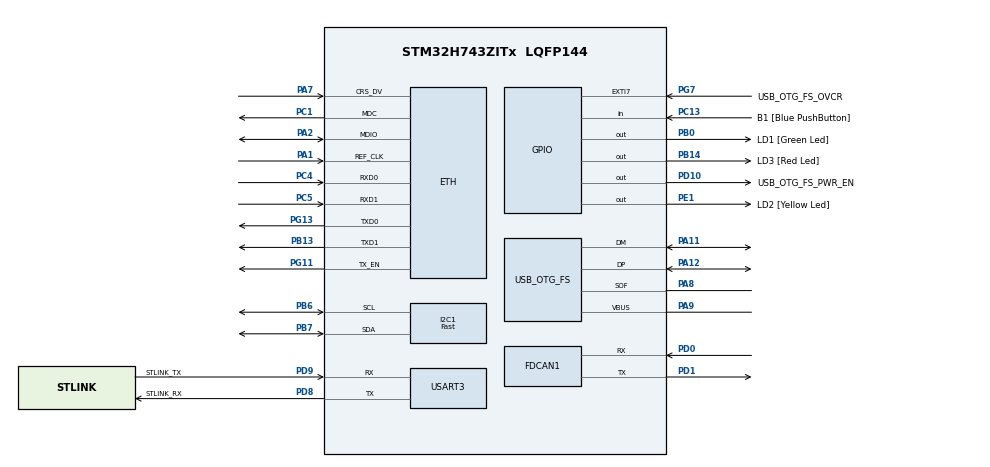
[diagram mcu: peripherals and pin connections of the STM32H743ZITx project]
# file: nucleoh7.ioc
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Dma.I2C1_RX.0.Direction=DMA_PERIPH_TO_MEMORY
Dma.I2C1_RX.0.EventEnable=DISABLE
Dma.I2C1_RX.0.FIFOMode=DMA_FIFOMODE_DISABLE
Dma.I2C1_RX.0.Instance=DMA1_Stream0
Dma.I2C1_RX.0.MemDataAlignment=DMA_MDATAALIGN_BYTE
Dma.I2C1_RX.0.MemInc=DMA_MINC_ENABLE
Dma.I2C1_RX.0.Mode=DMA_NORMAL
Dma.I2C1_RX.0.PeriphDataAlignment=DMA_PDATAALIGN_BYTE
Dma.I2C1_RX.0.PeriphInc=DMA_PINC_DISABLE
Dma.I2C1_RX.0.Polarity=HAL_DMAMUX_REQ_GEN_RISING
Dma.I2C1_RX.0.Priority=DMA_PRIORITY_LOW
Dma.I2C1_RX.0.RequestNumber=1
Dma.I2C1_RX.0.SignalID=NONE
Dma.I2C1_RX.0.SyncEnable=DISABLE
Dma.I2C1_RX.0.SyncPolarity=HAL_DMAMUX_SYNC_NO_EVENT
Dma.I2C1_RX.0.SyncRequestNumber=1
Dma.I2C1_RX.0.SyncSignalID=NONE
Dma.I2C1_TX.1.Direction=DMA_MEMORY_TO_PERIPH
Dma.I2C1_TX.1.EventEnable=DISABLE
Dma.I2C1_TX.1.FIFOMode=DMA_FIFOMODE_DISABLE
Dma.I2C1_TX.1.Instance=DMA1_Stream1
Dma.I2C1_TX.1.MemDataAlignment=DMA_MDATAALIGN_BYTE
Dma.I2C1_TX.1.MemInc=DMA_MINC_ENABLE
Dma.I2C1_TX.1.Mode=DMA_NORMAL
Dma.I2C1_TX.1.PeriphDataAlignment=DMA_PDATAALIGN_BYTE
Dma.I2C1_TX.1.PeriphInc=DMA_PINC_DISABLE
Dma.I2C1_TX.1.Polarity=HAL_DMAMUX_REQ_GEN_RISING
Dma.I2C1_TX.1.Priority=DMA_PRIORITY_LOW
Dma.I2C1_TX.1.RequestNumber=1
Dma.I2C1_TX.1.SignalID=NONE
Dma.I2C1_TX.1.SyncEnable=DISABLE
Dma.I2C1_TX.1.SyncPolarity=HAL_DMAMUX_SYNC_NO_EVENT
Dma.I2C1_TX.1.SyncRequestNumber=1
Dma.I2C1_TX.1.SyncSignalID=NONE
Dma.Request0=I2C1_RX
Dma.Request1=I2C1_TX
ETH.MediaInterface=HAL_ETH_RMII_MODE
FDCAN1.AutoRetransmission=ENABLE
I2C1.I2C_Speed_Mode=I2C_Fast
I2C1.Timing=0x00702991
Mcu.Family=STM32H7
Mcu.Name=STM32H743ZITx
Mcu.Package=LQFP144
NVIC.DMA1_Stream0_IRQn=true\:0\:0\:false\:false\:true\:false\:true
NVIC.DMA1_Stream1_IRQn=true\:0\:0\:false\:false\:true\:false\:true
NVIC.FDCAN1_IT0_IRQn=true\:0\:0\:false\:false\:true\:true\:true
NVIC.FDCAN1_IT1_IRQn=true\:0\:0\:false\:false\:true\:true\:true
NVIC.I2C1_ER_IRQn=true\:0\:0\:false\:false\:true\:true\:true
NVIC.I2C1_EV_IRQn=true\:0\:0\:false\:false\:true\:true\:true
NVIC.PriorityGroup=NVIC_PRIORITYGROUP_4
PA1.Mode=RMII
PA1.Signal=ETH_REF_CLK
PA11.Mode=Device_Only
PA11.Signal=USB_OTG_FS_DM
PA12.Mode=Device_Only
PA12.Signal=USB_OTG_FS_DP
PA2.Mode=RMII
PA2.Signal=ETH_MDIO
PA7.Mode=RMII
PA7.Signal=ETH_CRS_DV
PA8.Mode=Activate_SOF_FS
PA8.Signal=USB_OTG_FS_SOF
PA9.Mode=Activate_VBUS
PA9.Signal=USB_OTG_FS_VBUS
PB0.GPIO_Label=LD1 [Green Led]
PB0.Signal=GPIO_Output
PB13.Mode=RMII
PB13.Signal=ETH_TXD1
PB14.GPIO_Label=LD3 [Red Led]
PB14.Signal=GPIO_Output
PB6.Mode=I2C
PB6.Signal=I2C1_SCL
PB7.Mode=I2C
PB7.Signal=I2C1_SDA
PC1.Mode=RMII
PC1.Signal=ETH_MDC
PC13.GPIO_Label=B1 [Blue PushButton]
PC13.Signal=GPIO_Input
PC14-OSC32_IN\ (OSC32_IN).Mode=LSE-External-Oscillator
PC14-OSC32_IN\ (OSC32_IN).Signal=RCC_OSC32_IN
PC15-OSC32_OUT\ (OSC32_OUT).Mode=LSE-External-Oscillator
PC15-OSC32_OUT\ (OSC32_OUT).Signal=RCC_OSC32_OUT
PC4.Mode=RMII
PC4.Signal=ETH_RXD0
PC5.Mode=RMII
PC5.Signal=ETH_RXD1
PD0.Mode=FDCANMaster
PD0.Signal=FDCAN1_RX
PD1.Mode=FDCANMaster
PD1.Signal=FDCAN1_TX
PD10.GPIO_Label=USB_OTG_FS_PWR_EN
PD10.Signal=GPIO_Output
PD8.GPIO_Label=STLINK_RX
PD8.Mode=Asynchronous
PD8.Signal=USART3_TX
PD9.GPIO_Label=STLINK_TX
PD9.Mode=Asynchronous
PD9.Signal=USART3_RX
PE1.GPIO_Label=LD2 [Yellow Led]
PE1.Signal=GPIO_Output
PG11.Mode=RMII
PG11.Signal=ETH_TX_EN
PG13.Mode=RMII
PG13.Signal=ETH_TXD0
PG7.GPIO_Label=USB_OTG_FS_OVCR
PG7.Signal=GPXTI7
PH0-OSC_IN\ (PH0).Mode=HSE-External-Clock-Source
PH0-OSC_IN\ (PH0).Signal=RCC_OSC_IN
PH1-OSC_OUT\ (PH1).Signal=RCC_OSC_OUT
ProjectManager.HeapSize=0x200
ProjectManager.StackSize=0x400
ProjectManager.TargetToolchain=MDK-ARM V5.27
RCC.ADCFreq_Value=16125000
RCC.APB1Freq_Value=80000000
RCC.APB2Freq_Value=80000000
RCC.APB3Freq_Value=80000000
RCC.APB4Freq_Value=80000000
RCC.CortexFreq_Value=320000000
RCC.D1PPRE=RCC_APB3_DIV2
RCC.D2PPRE1=RCC_APB1_DIV2
RCC.D2PPRE2=RCC_APB2_DIV2
RCC.D3PPRE=RCC_APB4_DIV2
RCC.DIVM1=1
RCC.DIVN1=80
RCC.DIVQ1=4
RCC.FDCANCLockSelection=RCC_FDCANCLKSOURCE_HSE
RCC.HCLKFreq_Value=160000000
RCC.HPRE=RCC_HCLK_DIV2
RCC.HSE_VALUE=8000000
RCC.PLLFRACN=0
RCC.PLLSourceVirtual=RCC_PLLSOURCE_HSE
RCC.SYSCLKFreq_VALUE=320000000
RCC.SYSCLKSource=RCC_SYSCLKSOURCE_PLLCLK
RCC.USBCLockSelection=RCC_USBCLKSOURCE_HSI48
RCC.USBFreq_Value=48000000
USART3.VirtualMode-Asynchronous=VM_ASYNC
USB_OTG_FS.VirtualMode=Device_Only
board=NUCLEO-H743ZI2

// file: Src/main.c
/* USER CODE BEGIN Header */
/**
  ******************************************************************************
  * @file           : main.c
  * @brief          : Main program body
  ******************************************************************************
  * @attention
  *
  * <h2><center>&copy; Copyright (c) 2020 STMicroelectronics.
  * All rights reserved.</center></h2>
  *
  * This software component is licensed by ST under BSD 3-Clause license,
  * the "License"; You may not use this file except in compliance with the
  * License. You may obtain a copy of the License at:
  *                        opensource.org/licenses/BSD-3-Clause
  *
  ******************************************************************************
  */
/* USER CODE END Header */
#include "main.h"
#include "dma.h"
#include "eth.h"
#include "fdcan.h"
#include "i2c.h"
#include "usart.h"
#include "usb_otg.h"
#include "gpio.h"

/* USER CODE BEGIN Includes */

#include "testframework.h"
#include "stdio.h"

/* USER CODE END Includes */

void SystemClock_Config(void);

int main(void)
{

  /* MCU Configuration--------------------------------------------------------*/

  /* Reset of all peripherals, Initializes the Flash interface and the Systick. */
  HAL_Init();

  /* Configure the system clock */
  SystemClock_Config();

  /* Initialize all configured peripherals */
  MX_GPIO_Init();
  MX_DMA_Init();
  MX_ETH_Init();
  MX_USART3_UART_Init();
  MX_USB_OTG_FS_PCD_Init();
  MX_FDCAN1_Init();
  MX_I2C1_Init();
  /* USER CODE BEGIN 2 */

  testframework_init();

  char text[64] = {0};

  /* USER CODE END 2 */

  /* Infinite loop */
  while (1)
  {

      HAL_Delay(100);
      uint32_t now = HAL_GetTickFreq();
      testframework_tick();
      uint32_t duration = HAL_GetTickFreq() - now;
      snprintf(text, sizeof(char), "duration = %d ms", duration);
      testframework_puts(text);

  }
}

void SystemClock_Config(void)
{
  RCC_OscInitTypeDef RCC_OscInitStruct = {0};
  RCC_ClkInitTypeDef RCC_ClkInitStruct = {0};
  RCC_PeriphCLKInitTypeDef PeriphClkInitStruct = {0};

  /** Supply configuration update enable
  */
  HAL_PWREx_ConfigSupply(PWR_LDO_SUPPLY);
  /** Configure the main internal regulator output voltage
  */
  __HAL_PWR_VOLTAGESCALING_CONFIG(PWR_REGULATOR_VOLTAGE_SCALE1);

  while(!__HAL_PWR_GET_FLAG(PWR_FLAG_VOSRDY)) {}
  /** Initializes the RCC Oscillators according to the specified parameters
  * in the RCC_OscInitTypeDef structure.
  */
  RCC_OscInitStruct.OscillatorType = RCC_OSCILLATORTYPE_HSI48|RCC_OSCILLATORTYPE_HSE;
  RCC_OscInitStruct.HSEState = RCC_HSE_BYPASS;
  RCC_OscInitStruct.HSI48State = RCC_HSI48_ON;
  RCC_OscInitStruct.PLL.PLLState = RCC_PLL_ON;
  RCC_OscInitStruct.PLL.PLLSource = RCC_PLLSOURCE_HSE;
  RCC_OscInitStruct.PLL.PLLM = 1;
  RCC_OscInitStruct.PLL.PLLN = 80;
  RCC_OscInitStruct.PLL.PLLP = 2;
  RCC_OscInitStruct.PLL.PLLQ = 4;
  RCC_OscInitStruct.PLL.PLLR = 2;
  RCC_OscInitStruct.PLL.PLLRGE = RCC_PLL1VCIRANGE_3;
  RCC_OscInitStruct.PLL.PLLVCOSEL = RCC_PLL1VCOWIDE;
  RCC_OscInitStruct.PLL.PLLFRACN = 0;
  if (HAL_RCC_OscConfig(&RCC_OscInitStruct) != HAL_OK)
  {
    Error_Handler();
  }
  /** Initializes the CPU, AHB and APB buses clocks
  */
  RCC_ClkInitStruct.ClockType = RCC_CLOCKTYPE_HCLK|RCC_CLOCKTYPE_SYSCLK
                              |RCC_CLOCKTYPE_PCLK1|RCC_CLOCKTYPE_PCLK2
                              |RCC_CLOCKTYPE_D3PCLK1|RCC_CLOCKTYPE_D1PCLK1;
  RCC_ClkInitStruct.SYSCLKSource = RCC_SYSCLKSOURCE_PLLCLK;
  RCC_ClkInitStruct.SYSCLKDivider = RCC_SYSCLK_DIV1;
  RCC_ClkInitStruct.AHBCLKDivider = RCC_HCLK_DIV2;
  RCC_ClkInitStruct.APB3CLKDivider = RCC_APB3_DIV2;
  RCC_ClkInitStruct.APB1CLKDivider = RCC_APB1_DIV2;
  RCC_ClkInitStruct.APB2CLKDivider = RCC_APB2_DIV2;
  RCC_ClkInitStruct.APB4CLKDivider = RCC_APB4_DIV2;

  if (HAL_RCC_ClockConfig(&RCC_ClkInitStruct, FLASH_LATENCY_2) != HAL_OK)
  {
    Error_Handler();
  }
  PeriphClkInitStruct.PeriphClockSelection = RCC_PERIPHCLK_USART3|RCC_PERIPHCLK_FDCAN
                              |RCC_PERIPHCLK_I2C1|RCC_PERIPHCLK_USB;
  PeriphClkInitStruct.FdcanClockSelection = RCC_FDCANCLKSOURCE_HSE;
  PeriphClkInitStruct.Usart234578ClockSelection = RCC_USART234578CLKSOURCE_D2PCLK1;
  PeriphClkInitStruct.I2c123ClockSelection = RCC_I2C123CLKSOURCE_D2PCLK1;
  PeriphClkInitStruct.UsbClockSelection = RCC_USBCLKSOURCE_HSI48;
  if (HAL_RCCEx_PeriphCLKConfig(&PeriphClkInitStruct) != HAL_OK)
  {
    Error_Handler();
  }
  /** Enable USB Voltage detector
  */
  HAL_PWREx_EnableUSBVoltageDetector();
}

void Error_Handler(void)
{
}

/************************ (C) COPYRIGHT STMicroelectronics *****END OF FILE****/
